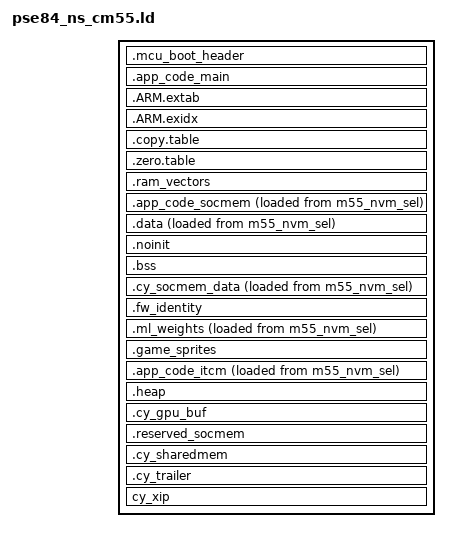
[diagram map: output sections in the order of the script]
/***************************************************************************//**
* \file pse84_ns_cm55.ld
* \version 1.0.0
*
* Linker file for the GNU C compiler.
*
* The main purpose of the linker script is to describe how the sections in the
* input files should be mapped into the output file, and to control the memory
* layout of the output file.
*
*
* \note The linker files included with the PDL template projects must be generic
* and handle all common use cases. Your project may not use every section
* defined in the linker files. In that case you may see warnings during the
* build process. In your project, you can simply comment out or remove the
* relevant code in the linker file.
*
********************************************************************************
* \copyright
* Copyright (c) (2020-2025), Cypress Semiconductor Corporation (an Infineon company) or
* an affiliate of Cypress Semiconductor Corporation.
* SPDX-License-Identifier: Apache-2.0
*
* Licensed under the Apache License, Version 2.0 (the "License");
* you may not use this file except in compliance with the License.
* You may obtain a copy of the License at
*
*     http://www.apache.org/licenses/LICENSE-2.0
*
* Unless required by applicable law or agreed to in writing, software
* distributed under the License is distributed on an "AS IS" BASIS,
* WITHOUT WARRANTIES OR CONDITIONS OF ANY KIND, either express or implied.
* See the License for the specific language governing permissions and
* limitations under the License.
*******************************************************************************/
/* Specify the output format for the linker script */
OUTPUT_FORMAT ("elf32-littlearm", "elf32-bigarm", "elf32-littlearm")
/* Search for libraries in the current directory */
SEARCH_DIR(.)
/* Specify the group of libraries to link against */
GROUP(-lgcc -lc -lnosys)
GROUP(libgcc.a libc.a libm.a libnosys.a)
/* Define the entry point of the program, which is the reset handler */
ENTRY(Reset_Handler)

/* Define the stack size for the application */
/* To set stack size in application add makefile ldflags: -Wl,--defsym=APP_MSP_STACK_SIZE=<CUSTOM_VALUE> */
PROVIDE(__StackSize = DEFINED(APP_MSP_STACK_SIZE) ? APP_MSP_STACK_SIZE : 0x1000);

/* Include the device memory definitions generated by the Device Configurator */
INCLUDE cymem_gnu_CM55_0.ld

/* Linker script to place sections and symbol values. Should be used together
 * with other linker script that defines memory regions FLASH and RAM.
 * It references following symbols, which must be defined in code:
 *   Reset_Handler : Entry of reset handler
 *
 * It defines following symbols, which code can use without definition:
 *   __exidx_start
 *   __exidx_end
 *   __copy_table_start__
 *   __copy_table_end__
 *   __zero_table_start__
 *   __zero_table_end__
 *   __data_start__
 *   __preinit_array_start
 *   __preinit_array_end
 *   __init_array_start
 *   __init_array_end
 *   __fini_array_start
 *   __fini_array_end
 *   __data_end__
 *   __bss_start__
 *   __bss_end__
 *   __end__
 *   end
 *   __HeapLimit
 *   __StackLimit
 *   __StackTop
 *   __stack
 */

/* Device definitions */
VECTORS_ALIGNMENT = 0x400;

/* The size of the MCU boot header area at the start of main code region */
MCUBOOT_HEADER_SIZE = 0x400;

/* Define the sections */
SECTIONS
{
    /* This section reserves a space for MCUBoot header */
    .mcu_boot_header (READONLY) : ALIGN(MCUBOOT_HEADER_SIZE)
    {
        . += MCUBOOT_HEADER_SIZE;
    } > m55_nvm_sel

    /* This section is intended to hold the main application code for the Cortex-M55 */
    /* Performance-sensitive or critical functions that need to be executed in sram are manually excluded */
    .app_code_main : ALIGN(VECTORS_ALIGNMENT)
    {
        __text_begin = .;
        __Vectors = . ;
        /* Keep the vector table */
        KEEP(*(.vectors))

        . = ALIGN(4);

        __Vectors_End = .;

        /* Keep initializers */
        KEEP(*(.init))
        /* Keep finalizers */
        KEEP(*(.fini))
        /* Static constructors */
        *crtbegin.*(.ctors)
        *crtbegin?.*(.ctors)
        *(EXCLUDE_FILE(*crtend?.* *crtend.*) .ctors)
        *(SORT(.ctors.*))
        *(.ctors)
        /* Static destructors and atexit() */
        *crtbegin.*(.dtors)
        *crtbegin?.*(.dtors)
        *(EXCLUDE_FILE(*crtend?.* *crtend.*) .dtors)
        *(SORT(.dtors.*))
        *(.dtors)
        /* Read only code (constants) */
        /* Sprite pixel arrays are steered to .game_sprites above the
         * fw_identity wall — without this EXCLUDE the ~36 KB of art pushes
         * .cy_socmem_data's load image across 0x60900000 (link error). */
        *(EXCLUDE_FILE(*flappy_sprites.o *pong_sprites.o *shooter_sprites.o *snake_sprites.o) .rodata)
        *(EXCLUDE_FILE(*flappy_sprites.o *pong_sprites.o *shooter_sprites.o *snake_sprites.o) .rodata.*)
        *(.constdata .constdata.* .conststring .conststring.*)
        /* Exclude certain files from this section as they will be placed in RAM */
        *(EXCLUDE_FILE(*cy_syslib.* *cy_syslib_ext.* *cy_smif.* *cy_smif_memnum.* *cy_smif_memslot.* *cy_smif_sfdp.* *cy_smif_hb_flash.* *mtb_hal_memoryspi.* *mtb_serial_memory.* *freertos/Source*.* *cy_clib_support*.* *cy_mutex_pool*.* *cy_time.* *cyabs_*.* *cy_worker_thread.* *cmsis*.*) .text*)

        . = ALIGN(4);

        __text_end = .;
    } > m55_nvm_sel

    /* Exception tables for ARM architecture */
    .ARM.extab (READONLY) : ALIGN(4)
    {
        *(.ARM.extab* .gnu.linkonce.armextab.*)
    } > m55_nvm_sel


    /* Exception index tables for ARM architecture */
    .ARM.exidx (READONLY) : ALIGN(4)
    {
        __exidx_start = .;

        *(.ARM.exidx* .gnu.linkonce.armexidx.*)

        __exidx_end = .;
    } > m55_nvm_sel


    /* Define copying of data from flash memory to RAM during the startup */
    .copy.table (READONLY) : ALIGN(4)
    {
        __copy_table_start__ = .;

        /* Initialized data in DTCM */
        LONG(LOADADDR(.data))       /* From load address in ext flash  */
        LONG(ADDR(.data))           /* To run address in DTCM  */
        LONG(SIZEOF(.data)/4)       /* Size in words */

        /* Initialized data in SOC memory */
        LONG(LOADADDR(.cy_socmem_data))     /* From load address in ext flash  */
        LONG(ADDR(.cy_socmem_data))         /* To run address in SOCMEM  */
        LONG(SIZEOF(.cy_socmem_data)/4)     /* Size in words */

        /* Large ML model weights, loaded above the fw_identity wall (see the
         * .ml_weights section). Empty (size 0) for models whose weights stay in
         * .cy_socmem_data, so this entry is then a harmless 0-word copy. */
        LONG(LOADADDR(.ml_weights))         /* From load address in ext flash  */
        LONG(ADDR(.ml_weights))             /* To run address in SOCMEM  */
        LONG(SIZEOF(.ml_weights)/4)         /* Size in words */

        /* Code in ITCM */
        LONG (LOADADDR(.app_code_itcm)) /* From load address in ext flash  */
        LONG (ADDR(.app_code_itcm))     /* To run address in ITCM  */
        LONG (SIZEOF(.app_code_itcm)/4) /* Size in words */

        /* Code in SOC memory */
        LONG (LOADADDR(.app_code_socmem)) /* From load address in ext flash  */
        LONG (ADDR(.app_code_socmem))     /* To run address in SOCMEM  */
        LONG (SIZEOF(.app_code_socmem)/4) /* Size in words */

        __copy_table_end__ = .;
    } > m55_nvm_sel

    /* Define zeroing of the uninitialized data section */
    .zero.table (READONLY): ALIGN(4)
    {
        __zero_table_start__ = .;

        LONG(__bss_start__)                       /* Start of the zero-initialized data section */
        LONG((__bss_end__ - __bss_start__)/4)     /* Size of the zero-initialized data section in words */

        __zero_table_end__ = .;
    } > m55_nvm_sel


    /* A section for the vector table */
    .ram_vectors (NOLOAD) : ALIGN(VECTORS_ALIGNMENT)
    {
        __ram_vectors_start__ = .;

        KEEP(*(.ram_vectors))

        __ram_vectors_end__ = .;
    } > m55_code_INTERNAL

    /* A section for less performance-sensitive or critical functions that might be executed in SOC memory */
    .app_code_socmem : ALIGN(4)
    {
        KEEP(*(.cy_socmem_code))

        . = ALIGN(4);
    }  > m55_code_secondary AT > m55_nvm_sel

    /* A section for initialized data memory */
    .data : ALIGN(4)
    {
        __data_start__ = .;

        *(vtable)
        *(.data*)

        . = ALIGN(4);

        /* Array of pointers to preinit functions */
        PROVIDE_HIDDEN (__preinit_array_start = .);

        KEEP(*(.preinit_array))

        PROVIDE_HIDDEN (__preinit_array_end = .);

        . = ALIGN(4);

        /* Array of pointers to init functions */
        PROVIDE_HIDDEN (__init_array_start = .);

        KEEP(*(SORT(.init_array.*)))
        KEEP(*(.init_array))

        PROVIDE_HIDDEN (__init_array_end = .);

        . = ALIGN(4);

        /* Array of pointers to finalizer functions */

        PROVIDE_HIDDEN (__fini_array_start = .);

        KEEP(*(SORT(.fini_array.*)))
        KEEP(*(.fini_array))

        PROVIDE_HIDDEN (__fini_array_end = .);

        KEEP(*(.jcr*))

        . = ALIGN(4);

        KEEP(*(.cy_dtcm))

        . = ALIGN(4);

        __data_end__ = .;
    } > m55_data_INTERNAL AT > m55_nvm_sel

    /* A section for variables that should not be initialized during the device startup */
    .noinit (NOLOAD) : ALIGN(8)
    {
        __noinit_start__ = .;

        KEEP(*(.noinit))

        . = ALIGN(4);

        __noinit_end__ = .;
    } > m55_data_INTERNAL

    /* A section for non-initialized data memory */
    .bss(NOLOAD) : ALIGN(4)
    {
        __bss_start__ = .;

        *(.bss*)
        *(COMMON)

        . = ALIGN(4);

        __bss_end__ = .;
    } > m55_data_INTERNAL

    __StackTop = ORIGIN(m55_data_INTERNAL) + LENGTH(m55_data_INTERNAL);
    __StackLimit = __StackTop - __StackSize;
    PROVIDE(__stack = __StackTop);

    /* Check if .data + .noinit + .bss + stack exceeds RAM limit in region m55_data_INTERNAL */
    ASSERT(
      __StackLimit >= __bss_end__,
      "Error: m55_data_INTERNAL region overflowed with stack. Ensure that the stack size is within the available RAM."
    )

    /* A section for SOC memory data */
    .cy_socmem_data : ALIGN(4)
    {
        KEEP(*(.cy_socmem_data))

        . = ALIGN(4);

    }  > m55_data_secondary AT > m55_nvm_sel

    /* Firmware identity record — Option B: fixed address in the UNUSED TAIL of the m55_nvm slot
     * (AI Kit slot 0x60580000+0x600000 = 6MB; image ends ~1-2MB in; record at +0x380000 = 0x60900000,
     * well below m55_trailer @0x60B80000 and the filesystem). Placed AFTER all load sections so it does
     * NOT shift the vector table / code (which stay at 0x60580400 → CM55 display unaffected).
     * Readers use the fixed 0x60900000. See TESAIoT_PLAN/Firmware_Identity. */
    .fw_identity ORIGIN(m55_nvm_sel) + 0x380000 (READONLY) :
    {
        __fw_identity_start = .;
        KEEP(*(.fw_identity))
        . = __fw_identity_start + 0x100;
        __fw_identity_end = .;
    } > m55_nvm_sel

    /* Large ML model weights (e.g. the audio Baby Cry net, ~103 KB) whose flash
     * image would otherwise push .cy_socmem_data past the .fw_identity wall at
     * 0x60900000. Placed AFTER .fw_identity so its load address (AT > m55_nvm_sel)
     * begins at 0x60900100, in the free ~2.5 MB tail up to m55_trailer @0x60B80000.
     * It RUNS in SOCMEM (m55_data_secondary) for U55 DMA reach and is copied there
     * at boot by the .copy.table entry above. Empty for models that keep their
     * weights in .cy_socmem_data (selected per model via CY_ML_MODEL_MEM). */
    .ml_weights : ALIGN(4)
    {
        KEEP(*(.ml_weights))
        . = ALIGN(4);
    } > m55_data_secondary AT > m55_nvm_sel

    /* Game sprite pixel art (ui.Sprite / bentogame on the MPY firmware) —
     * const data, GPU-readable in place over XIP (the Game project keeps the
     * same arrays in plain flash rodata), so no SOCMEM copy: flash-resident
     * above the fw_identity wall, in the same free tail as .ml_weights. */
    .game_sprites : ALIGN(4)
    {
        *flappy_sprites.o(.rodata .rodata.*)
        *pong_sprites.o(.rodata .rodata.*)
        *shooter_sprites.o(.rodata .rodata.*)
        *snake_sprites.o(.rodata .rodata.*)
        . = ALIGN(4);
    } > m55_nvm_sel

    /* Load image steered above the fw_identity wall at 0x60900000, the same way
     * .ml_weights and .game_sprites are. The run address stays in ITCM; only the
     * load address moves, and the copy table below already derives it with
     * LOADADDR(), so the boot copy follows automatically. Kept below the wall this
     * section's ~61 KB pushes .cy_socmem_data's load image across 0x60900000 and
     * the link fails once the Bluetooth host is compiled in. */
    /* A section for performance-sensitive or critical functions that need to be executed in ITCM */
    .app_code_itcm : ALIGN(16)
    {
        /* Reserving the first 16 bytes to avoid debug symbols (that have default address 0x0) to be confused with actual code  */
        . += 16;
        KEEP(*(.cy_itcm))
        KEEP(*(.cy_sram_code))
        KEEP(*(.cy_ramfunc))
        KEEP(*(.text.cy_os_common))
        *cy_syslib_ext.*(.text*)
        *cy_syslib.*(.text*)
        *cy_smif.*(.text*)
        *cy_smif_memnum.*(.text*)
        *cy_smif_memslot.*(.text*)
        *cy_smif_sfdp.*(.text*)
        *cy_smif_hb_flash.*(.text*)
        *mtb_hal_memoryspi.*(.text*)
        *mtb_serial_memory.*(.text*)
        *freertos/Source*.*(.text*)
        *cy_clib_support*.*(.text*)
        *cy_mutex_pool*.*(.text*)
        *cy_time.*(.text*)
        *cyabs_*.*(.text*)
        *cy_worker_thread.*(.text*)
        *cmsis*.*(.text*)

        . = ALIGN(4);
    } > m55_code_INTERNAL AT > m55_nvm_sel

    /* A section for the heap memory */
    .heap(NOLOAD) : ALIGN(8)
    {
        __HeapBase = .;
        __end__ = .;
        end = __end__;

        KEEP(*(.heap*))

        . = ORIGIN(m55_data_secondary) + LENGTH(m55_data_secondary);

        __HeapLimit = .;
    } > m55_data_secondary

    /* The heap takes whatever m55_data_secondary has left after .cy_socmem_data
     * and .ml_weights, so ML model weights and arenas trade against it byte for
     * byte. Today: .cy_socmem_data 35,456 + .ml_weights 633,832 + heap 2,197,912
     * = 2,867,200, the whole region. Edge AI already holds 22% of it.
     *
     * That pool is where LVGL allocates every page tree, the HSM Security
     * provisioning screens among them (lv_conf.h sets LV_USE_STDLIB_MALLOC to
     * LV_STDLIB_CLIB, and FreeRTOSConfig.h selects heap_3, so LVGL, task stacks
     * and newlib all draw from this one arena). Adding a model, enlarging a net,
     * or enabling one of the stubbed model rows grows .ml_weights and shrinks the
     * heap silently: no link error, no warning, and no symptom until some
     * allocation returns NULL on a screen that has nothing to do with Edge AI.
     *
     * This floor is a tripwire, not a measured minimum. 2.10 MB is known to work;
     * 1.5 MB is set well below it so ordinary work never trips it, and a model
     * set roughly twice today's does. If it fires, the answer is to measure
     * mallinfo().fordblks under load and decide deliberately - not to lower it. */
    ASSERT(__HeapLimit - __HeapBase >= 0x180000,
      "CM55 heap has fallen below the 1.5 MB floor. .ml_weights has grown into the heap that LVGL and the HSM provisioning screens allocate from. Measure before changing this."
    )

    /* A section for the GPU buffer */
    .cy_gpu_buf(NOLOAD) :
    {
        KEEP(*(.cy_gpu_buf))
    } > gfx_mem

    .reserved_socmem(NOLOAD) :
    {
        . = ORIGIN(m33_m55_shared) + LENGTH(m33_m55_shared); /* reserved SOC memory */
    } > m33_m55_shared


    /* A section for shared RAM memory where only the Cortex-M55 can allocate data but all cores can access */
    .cy_sharedmem(NOLOAD) : ALIGN(4)
    {
        KEEP(*(.cy_sharedmem))

        . = ALIGN(4);
    } > m55_allocatable_shared

    /* Reserve a trail space for the signature for the bootloader - do not place any code here */
    .cy_trailer(NOLOAD) :
    {
    } > m55_trailer_sel

    cy_xip (NOLOAD):
    {
        . = ALIGN(4);
        __cy_xip_start = .;
        KEEP(*(.cy_xip))
        . = ALIGN(4);
        __cy_xip_end = .;
    } > cm55_psram

}
